# ATmega8535 device description
Architecture: AVR8; Family: megaAVR
Registers are 8-bit, access not given, no defined reset value unless marked. A register's access mark holds for its fields unless they carry their own. Offsets are from the block's base; [hi:lo] are bit positions; 'fields as' and 'values as' point back to an identical list.

## EEPROM
Instances: EEPROM 0x00
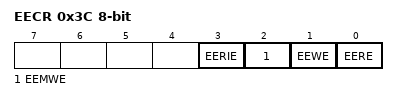
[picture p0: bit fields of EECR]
0x3C EECR — EEPROM Control Register
  [3] EERIE — EEPROM Ready Interrupt Enable
  [2] EEMWE — EEPROM Master Write Enable
  [1] EEWE — EEPROM Write Enable
  [0] EERE — EEPROM Read Enable
0x3D EEDR — EEPROM Data Register
0x3E EEAR 16-bit bits used 8:0 — EEPROM Address Register Bytes

## TC0 (TC8 module) — Timer/Counter, 8-bit
Instances: TC0 0x00
0x50 SFIOR — Special Function IO Register
  [0] PSR10 — Prescaler Reset Timer/Counter1 and Timer/Counter0
0x52 TCNT0 — Timer/Counter Register
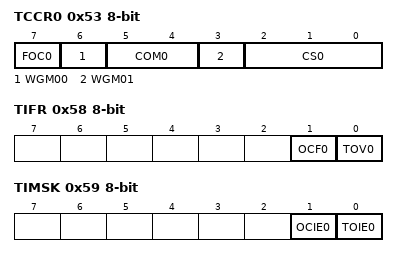
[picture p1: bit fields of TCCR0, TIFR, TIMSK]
0x53 TCCR0 — Timer/Counter Control Register
  [7] FOC0 — Force Output Compare
  [6] WGM00 — Waveform Generation Mode 0
    0=Normal; 2=PWM, Phase Correct; 1=CTC; 3=Fast PWM
  [5:4] COM0 — Compare Match Output Modes
  [3] WGM01 — Waveform Generation Mode 1
  [2:0] CS0 — Clock Selects
    0=No Clock Source (Stopped); 1=Running, No Prescaling; 2=Running, CLK/8; 3=Running, CLK/64; 4=Running, CLK/256; 5=Running, CLK/1024; 6=Running, ExtClk Tx Falling Edge; 7=Running, ExtClk Tx Rising Edge
0x58 TIFR — Timer/Counter Interrupt Flag register
  [1] OCF0 — Output Compare Flag 0
  [0] TOV0 — Timer/Counter0 Overflow Flag
0x59 TIMSK — Timer/Counter Interrupt Mask Register
  [1] OCIE0 — Timer/Counter0 Output Compare Match Interrupt register
  [0] TOIE0 — Timer/Counter0 Overflow Interrupt Enable
0x5C OCR0 — Output Compare Register

## TC1 (TC16 module) — Timer/Counter, 16-bit
Instances: TC1 0x00
0x46 ICR1 16-bit — Timer/Counter1 Input Capture Register Bytes
0x48 OCR1B 16-bit — Timer/Counter1 Output Compare Register Bytes
0x4A OCR1A 16-bit — Timer/Counter1 Output Compare Register Bytes
0x4C TCNT1 16-bit — Timer/Counter1 Bytes
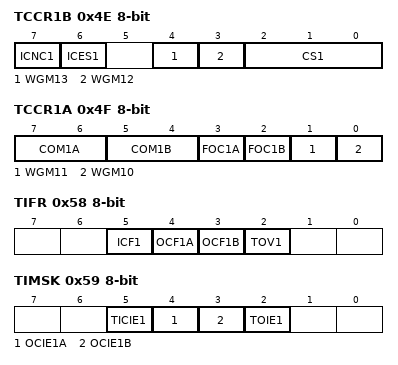
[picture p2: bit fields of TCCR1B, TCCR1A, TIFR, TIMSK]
0x4E TCCR1B — Timer/Counter1 Control Register B
  [7] ICNC1 — Input Capture 1 Noise Canceler
  [6] ICES1 — Input Capture 1 Edge Select
  [4] WGM13 (bit 2 of the value upward) — Waveform Generation Mode
  [3] WGM12 (bit 2 of the value upward) — Waveform Generation Mode
  [2:0] CS1 — Prescaler source of Timer/Counter 1
    0=No Clock Source (Stopped); 1=Running, No Prescaling; 2=Running, CLK/8; 3=Running, CLK/64; 4=Running, CLK/256; 5=Running, CLK/1024; 6=Running, ExtClk Tx Falling Edge; 7=Running, ExtClk Tx Rising Edge
0x4F TCCR1A — Timer/Counter1 Control Register A
  [7:6] COM1A — Compare Output Mode 1A, bits
  [5:4] COM1B — Compare Output Mode 1B, bits
  [3] FOC1A — Force Output Compare 1A
  [2] FOC1B — Force Output Compare 1B
  [1] WGM11 — Waveform Generation Mode
  [0] WGM10 — Waveform Generation Mode
0x58 TIFR — Timer/Counter Interrupt Flag register
  [5] ICF1 — Input Capture Flag 1
  [4] OCF1A — Output Compare Flag 1A
  [3] OCF1B — Output Compare Flag 1B
  [2] TOV1 — Timer/Counter1 Overflow Flag
0x59 TIMSK — Timer/Counter Interrupt Mask Register
  [5] TICIE1 — Timer/Counter1 Input Capture Interrupt Enable
  [4] OCIE1A — Timer/Counter1 Output CompareA Match Interrupt Enable
  [3] OCIE1B — Timer/Counter1 Output CompareB Match Interrupt Enable
  [2] TOIE1 — Timer/Counter1 Overflow Interrupt Enable

## TC2 (TC8_ASYNC module) — Timer/Counter, 8-bit Async
Instances: TC2 0x00
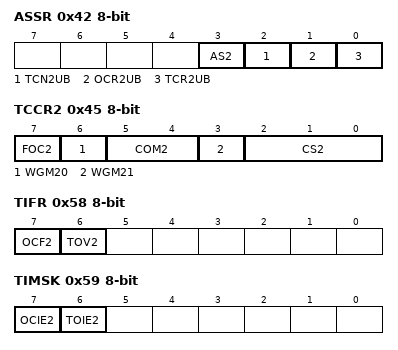
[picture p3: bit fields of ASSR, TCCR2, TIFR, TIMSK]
0x42 ASSR — Asynchronous Status Register
  [3] AS2 — Asynchronous Timer/counter2
  [2] TCN2UB — Timer/Counter2 Update Busy
  [1] OCR2UB — Output Compare Register2 Update Busy
  [0] TCR2UB — Timer/counter Control Register2 Update Busy
0x43 OCR2 — Timer/Counter2 Output Compare Register
0x44 TCNT2 — Timer/Counter2
0x45 TCCR2 — Timer/Counter2 Control Register
  [7] FOC2 — Force Output Compare
  [6] WGM20 — Waveform Genration Mode
    0=Normal; 2=PWM, Phase Correct; 1=CTC; 3=Fast PWM
  [5:4] COM2 — Compare Output Mode bits
  [3] WGM21 — Waveform Generation Mode
  [2:0] CS2 — Clock Select bits
    0=No Clock Source (Stopped); 1=Running, No Prescaling; 2=Running, CLK/8; 3=Running, CLK/32; 4=Running, CLK/64; 5=Running, CLK/128; 6=Running, CLK/256; 7=Running, CLK/1024
0x50 SFIOR — Special Function IO Register
  [1] PSR2 — Prescaler Reset Timer/Counter2
0x58 TIFR — Timer/Counter Interrupt Flag Register
  [7] OCF2 — Output Compare Flag 2
  [6] TOV2 — Timer/Counter2 Overflow Flag
0x59 TIMSK — Timer/Counter Interrupt Mask register
  [7] OCIE2 — Timer/Counter2 Output Compare Match Interrupt Enable
  [6] TOIE2 — Timer/Counter2 Overflow Interrupt Enable

## EXINT — External Interrupts
Instances: EXINT 0x00
0x54 MCUCSR — MCU Control And Status Register
  [6] ISC2 — Interrupt Sense Control 2
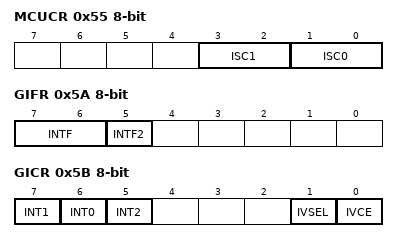
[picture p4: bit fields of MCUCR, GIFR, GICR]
0x55 MCUCR — General Interrupt Control Register
  [3:2] ISC1 — Interrupt Sense Control 1 Bits
    0=Low Level of INTX; 1=Any Logical Change of INTX; 2=Falling Edge of INTX; 3=Rising Edge of INTX
  [1:0] ISC0 — Interrupt Sense Control 0 Bits
    values as ISC1
0x5A GIFR — General Interrupt Flag Register
  [7:6] INTF — External Interrupt Flags
  [5] INTF2 — External Interrupt Flag 2
0x5B GICR — General Interrupt Control Register
  [7] INT1 — External Interrupt Request 1 Enable
  [6] INT0 — External Interrupt Request 0 Enable
  [5] INT2 — External Interrupt Request 2 Enable
  [1] IVSEL — Interrupt Vector Select
  [0] IVCE — Interrupt Vector Change Enable

## WDT — Watchdog Timer
Instances: WDT 0x00
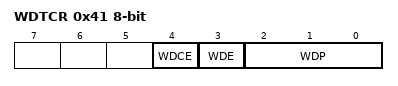
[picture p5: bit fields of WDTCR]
0x41 WDTCR — Watchdog Timer Control Register
  [4] WDCE — Watchdog Change Enable
  [3] WDE — Watch Dog Enable
  [2:0] WDP — Watch Dog Timer Prescaler bits
    0=Oscillator Cycles 16K; 1=Oscillator Cycles 32K; 2=Oscillator Cycles 64K; 3=Oscillator Cycles 128K; 4=Oscillator Cycles 256K; 5=Oscillator Cycles 512K; 6=Oscillator Cycles 1024K; 7=Oscillator Cycles 2048K

## CPU — CPU Registers
Instances: CPU 0x00
Parameters: CORE_VERSION=V2E
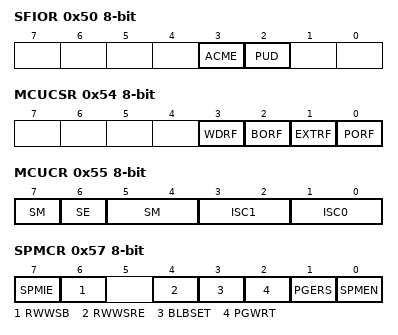
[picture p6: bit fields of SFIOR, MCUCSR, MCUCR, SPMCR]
0x50 SFIOR — Special Function IO Register
  [3] ACME — Anlog Comparator Multiplexer Enable
  [2] PUD — Pull-up Disable
0x51 OSCCAL — Oscillator Calibration Value
  [7:0] OSCCAL — Oscillator Calibration
0x54 MCUCSR — MCU Control And Status Register
  [3] WDRF — Watchdog Reset Flag
  [2] BORF — Brown-out Reset Flag
  [1] EXTRF — External Reset Flag
  [0] PORF — Power-on reset flag
0x55 MCUCR — MCU Control Register
  [6] SE — Sleep Enable
  [7,5:4] SM — Sleep Mode Select
    0=IDLE; 1=ADC (ADC Noise Reduction (If Available)); 2=PDOWN (Power Down); 3=PSAVE (Power Save); 10=STDBY (Standby); 11=ESTDBY (Extended Standby)
  [3:2] ISC1 — Interrupt Sense Control 1 Bits
  [1:0] ISC0 — Interrupt Sense Control 0 Bits
0x57 SPMCR
  [7] SPMIE — SPM Interrupt Enable
  [6] RWWSB — Read-While-Write Section Busy
  [4] RWWSRE — Read-While-Write Section Read Enable
  [3] BLBSET — Boot Lock Bit Set
  [2] PGWRT — Page Write
  [1] PGERS — Page Erase
  [0] SPMEN — Store Program Memory Enable
0x5D SP 16-bit bits used 10:0 — Stack Pointer
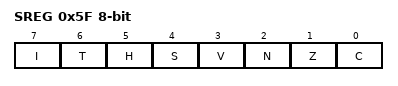
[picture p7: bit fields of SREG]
0x5F SREG — Status Register
  [7] I — Global Interrupt Enable
  [6] T — Bit Copy Storage
  [5] H — Half Carry Flag
  [4] S — Sign Bit
  [3] V — Two's Complement Overflow Flag
  [2] N — Negative Flag
  [1] Z — Zero Flag
  [0] C — Carry Flag
Value list OSCCAL_VALUE_ADDRESSES: 0=1_Mhz; 1=2_Mhz; 2=4_Mhz; 3=8_Mhz
